# netx90_app register map
File version: 1.0
CPU: CM4 r0p1, little endian, MPU, FPU, 4 interrupt priority bits, 78 interrupts
Registers are 32-bit, read-write, reset 0x0 unless marked. A register's access mark holds for its fields unless they carry their own. Offsets are from the block's base; [hi:lo] are bit positions; {n}, {i} and the like mark numbered series.

## i2c_app
Base 0xFF801080
Same registers: i2c_xpic_app 0xFF900340
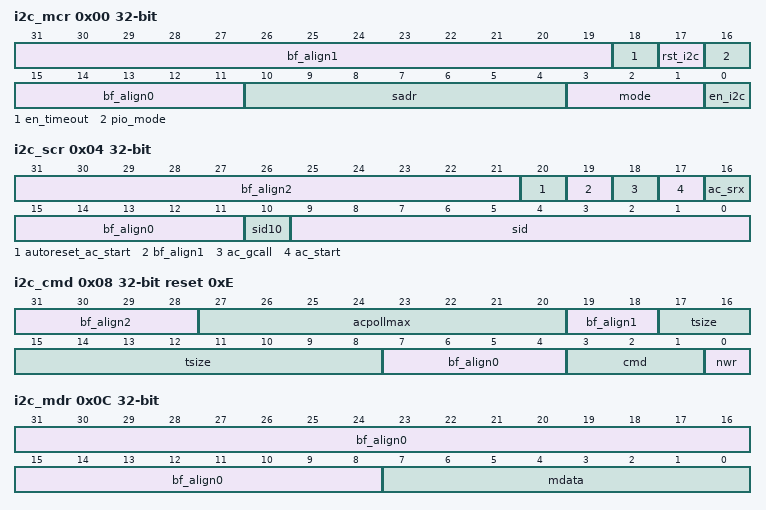
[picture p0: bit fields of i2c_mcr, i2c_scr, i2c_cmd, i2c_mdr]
0x00 i2c_mcr (reset mask 0x707FF) — I2C master control register:
  [31:19] bf_align1 — bitField alignment value for aeabi compatibility
  [18] en_timeout — Enable I2C command timeout detection. Enabling the timeout detection is recommended to prevent the module from stalling if another device holds the I2C signals permanently low. For details, see the description of bit i2s_sr.timeout.
  [17] rst_i2c — Reset the I2C bus-state-detection logic. To avoid conflicts with other masters, some I2C bus states, which are important when there are multiple masters on the I2C bus, are always monitored, even if the I2C module is disabled. For details, see bits i2c_sr.started and i2c.bus_master. However, it may happen that bus states are detected which lock up the I2C module. E.g. hazards during power-up or IO configuration or sequences, which are not I2C compliant, can cause a lock-up. This bit can be used to escape from such a situation. Write a '1' here to reset the I2C bus-state-detection logic of register i2c_sr. Note: This bit is new since netX51/52. It is always '0' when read.
  [16] pio_mode — If this bit is set, SCL and SDA can be controlled directly by register i2c_pio (e.g. to access devices being incompatible with I2C). In PIO mode, the I2C controller state machine is disabled: FIFOs are not used, no IRQs will be set, and no DMA controlling is possible.
  [15:11] bf_align0 — bitField alignment value for aeabi compatibility
  [10:4] sadr — 7-bit slave address sent after (r)START: For 10-bit addressing, the first byte (10-bit start '11110', address bits[9:8] must be programmed here. The second start byte (lower slave address bits) must be on top of the master FIFO (i2c_mdr). This register must be rewritten (even if the value does not change) to address another slave in the 10-bit mode (run 2-byte start sequence). The register must not be rewritten before a repeated START on the same 10-bit addressed slave (run 1-byte start sequence e.g. write to read change).
  [3:1] mode — I2C-speed-mode: If this device is used as a slave only, the mode should be set to the data rate generated by the fastest master on the I2C-bus for appropriate input filtering and spike suppression. The programmed mode defines also the SDA hold time after a falling edge of SCL. { | | Value Mode SDA hold time after SCL low 000 Fast/Standard mode, 50 kbit/s 630ns 001 Fast/Standard mode, 100 kbit/s 630ns 010 Fast/Standard mode, 200 kbit/s 630ns 011 Fast/Standard mode, 400 kbit/s 310ns 100 High-speed mode, 800 kbit/s 150ns 101 High-speed mode, 1.2 Mbit/s 70ns 110 High-speed mode, 1.7 Mbit/s 70ns 111 High-speed mode, 3.4 Mbit/s 30ns}
  [0] en_i2c — Global I2C controller enable 1: Enable I2C controller 0: Disable I2C controller Disabling the I2C module during a transfer will immediately disconnect the I2C module from the bus without generating a STOP. The internal I2C state machine will be set back to initial/idle state. The I2C bus-state-detection for the bits i2c_sr.bus_master and i2c_sr.started are performed even if the module is disabled. For details, see these bits.
0x04 i2c_scr (reset mask 0x1707FF) — I2C slave control register:
  [31:21] bf_align2 — bitField alignment value for aeabi compatibility
  [20] autoreset_ac_start — Auto reset ac_start (ac_start must be set again after any (r)START): 0: ac_start will not be reset automatically (netX 50-compatible, but not recommended) 1: Reset ac_start after this slave acknowledged a start sequence (recommended)
  [19] bf_align1 — bitField alignment value for aeabi compatibility
  [18] ac_gcall — General call acknowledge: 0: Do not generate an acknowledge after a general call 1: Generate an acknowledge after a general call
  [17] ac_start — Enable start sequence acknowledge: If the received address matches the sid-bits, the start-byte (2 bytes if sid10 is set) will be acknowledged. If the master requests a read transfer, a slave FIFO read access will be carried out immediately after the acknowledge, i.e. valid data must be present in the slave FIFO before enabling the acknowledge. If autoreset_ac_start is enabled, the controller will automatically reset this bit. If it is not enabled, the software should reset this bit after the start sequence has been acknowledged to avoid acknowledge and FIFO errors after the next (r)START. 0: Do not generate an acknowledge after the start sequence 1: Generate an acknowledge after the start sequence This bit is writable, but can also be changed by hardware.
  [16] ac_srx — Enable slave-receive-data acknowledge: 0: Do not acknowledge receive bytes 1: Acknowledge receive bytes If the slave FIFO is full, receive data will not be acknowledged.
  [15:11] bf_align0 — bitField alignment value for aeabi compatibility
  [10] sid10 — 10-bit slave device ID/address: 0: Wait for 7-bit slave address after (r)START 1: Wait for 10-bit slave address after (r)START
  [9:0] sid — Slave device ID/address: External masters can address this device (this I2C module in slave mode) by the ID/address programmed here. If sid10 is not set, bits 9 to 7 will be ignored.
0x08 i2c_cmd reset 0xE (reset mask 0xFF3FF0F) — I2C master command register:
  [31:28] bf_align2 — bitField alignment value for aeabi compatibility
  [27:20] acpollmax — Number of tries (acpollmax+1, i.e. 1 to 256) for start sequence acknowledge polling: For 7-bit addressing, acknowledge polling START and the first byte containing the slave address (i2c_mcr.sadr) will be repeated up to acpollmax+1 times until a slave generates an acknowledge. If no acknowledge is received within acpollmax+1 tries, IRQ cmd_err will be generated. For 10-bit-addressing, the 2-byte start sequence is performed. The second address byte (lower address bits) must be on top of the master FIFO (i2c_mdr). For subsequent transfers, the value programmed in tsize has to ignore this byte. The programmed value of acpollmax will count down during acknowledge polling after each start sequence. This bit is writable, but can also be changed by hardware.
  [19:18] bf_align1 — bitField alignment value for aeabi compatibility
  [17:8] tsize — Transfer tsize+1 bytes (1...1024): If no acknowledge is generated by the slave (receiver), write transfers will be terminated and IRQ cmd_err will be generated. For 10-bit-addressing, the second start-byte (lower address bits) must be on top of the master FIFO. For subsequent transfers, the value programmed here has to ignore this byte. This value will count down during transfers after each byte. This bit is writable, but can also be changed by hardware.
  [7:4] bf_align0 — bitField alignment value for aeabi compatibility
  [3:1] cmd — I2C sequence command: All commands will generate IRQ cmd_ok or IRQ cmd_err. A successful command termination will always generate IRQ cmd_ok. In case of an unsuccessful command termination, IRQ cmd_err will be set. { | | 000 START Generate (r)START-condition 001 S_AC Acknowledge-polling: generate up to acpollmax+1 START-sequences (until acknowledged by slave) 010 S_AC_T Run S_AC, then transfer tsize+1 bytes from/to master FIFO. Not to be continued 011 S_AC_TC Run S_AC, then transfer tsize+1 bytes from/to master FIFO. To be continued 100 CT Continued transfer not to be continued 101 CTC Continued transfer to be continued 110 STOP Generate STOP-condition 111 IDLE Nothing to do, last command finished, break current command } Sequences including read transfers that are not to be continued (S_AC_T, CT with 'nwr' bit set) will not generate an acknowledge after the last received byte (read transfer ends). Read transfers that are to be continued (S_AC_TC, CTC) will generate an acknowledge after the last received byte and must be followed by CT or CTC. Before continued transfers (CT, CTC), a command including START (START, S_AC, S_AC_T, S_AC_TC) must be executed to generate a valid I2C sequence. STOP must always be executed by software to free the bus after transfer end. STOP is not included in any command sequence and never executed automatically by this module. Some commands are handled as sequences (i.e. after setting S_AC_T, first S_AC then CT will be seen when read). You need not poll for IDLE here before setting up a new command, but you have to wait for cmd_ok or cmd_err status flags of register i2c_irqsr to be set. This bit is writable, but can also be changed by hardware.
  [0] nwr — Transfer direction (not-write/read): 0: cmd will be executed as write 1: cmd will be executed as read Master FIFO-requests (IRQ and DMA) are generated depending on this direction flag.
0x0C i2c_mdr (reset mask 0xFF) — I2C master data register (master FIFO): There is only one FIFO for both receive and transmit master data with a depth of 16 bytes. For a master write access, data read from the FIFO is is sent via I2C. For a master read access, data received from I2C is written into the FIFO. In case of imminent data transfer failure (read transfer and FIFO is full or write transfer and FIFO is empty), the transfer will be paused. To continue the transfer, the FIFO must be handled first (filled for transmit, read out for receive). Note: The FIFO behavior has been changed: For netX 51/52/56 and older versions, the current command was aborted and the cmd_err was raised.
  [31:8] bf_align0 — bitField alignment value for aeabi compatibility
  [7:0] mdata — I2C master transmit or receive data: Transmit data will be removed from the FIFO after the receiving slave has generated the corresponding acknowledge. Transmit data that has not been acknowledged will not be removed from the FIFO.
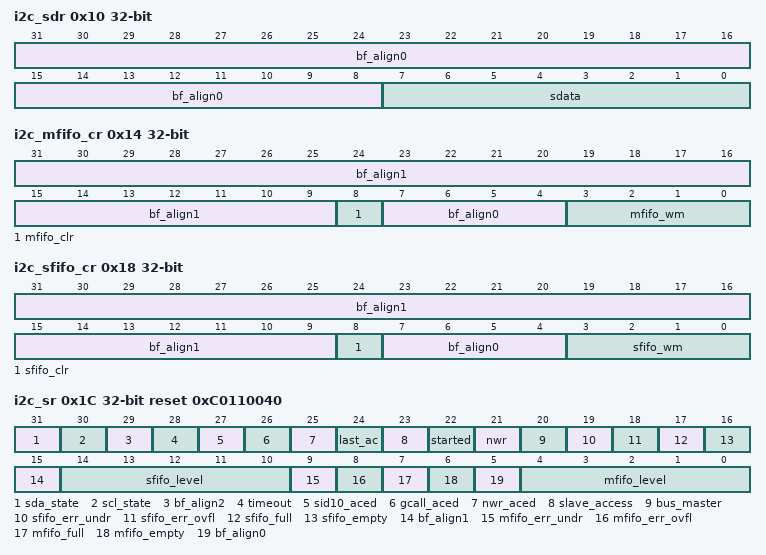
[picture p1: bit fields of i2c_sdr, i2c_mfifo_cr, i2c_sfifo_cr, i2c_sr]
0x10 i2c_sdr (reset mask 0xFF) — I2C slave data register (slave FIFO): There is only one FIFO for both receive and transmit slave data with a depth of 16 bytes. For a read access of an external master, data sent by this slave is read from the FIFO. For a write access of an external master, data received by this slave is written into the FIFO. A transfer is initiated after the detection of I2C-start-sequence to the device address (i2c_scr.sid, sreq IRQ) which is acknowledged by this device (i2c_scr.ac_start). For read transfers, sent data is read from the FIFO immediately after the detection of the acknowledge on the I2C-bus. SDA will be driven with the next data MSB immediately after the acknowledge SCL high phase. In case of a master read transfer and slave FIFO underrun, corrupted data will be sent to the master and the IRQ fifo_err will be set. In case of a master write transfer and slave FIFO is full, no acknowledge will be generated for the last received byte. No FIFO overflow will occur, but the last transferred byte (not acknowledged) will be lost and has to be sent again by the master.
  [31:8] bf_align0 — bitField alignment value for aeabi compatibility
  [7:0] sdata — I2C slave transmit or receive data: The software must handle i2c_scr.ac_start correctly to avoid FIFO errors after (r)START.
0x14 i2c_mfifo_cr (reset mask 0x10F) — I2C master FIFO control register:
  [31:9] bf_align1 — bitField alignment value for aeabi compatibility
  [8] mfifo_clr — Clear master data FIFO, write only bit. This bit is writable, but can also be changed by hardware.
  [7:4] bf_align0 — bitField alignment value for aeabi compatibility
  [3:0] mfifo_wm — Master FIFO watermark for the generation of IRQ mfifo_req: If the master is the transmitter (enabled and i2c_cmd.nwr is 0), IRQ mfifo_req is generated if mfifo_level<mfifo_wm. If the master is the receiver (enabled and i2c_cmd.nwr is 1), IRQ mfifo_req is generated if mfifo_level>mfifo_wm. Note: Set the watermark to 0 at transfer end to avoid further IRQ generation.
0x18 i2c_sfifo_cr (reset mask 0x10F) — I2C slave FIFO control register:
  [31:9] bf_align1 — bitField alignment value for aeabi compatibility
  [8] sfifo_clr — Clear slave data FIFO, write only bit. This bit is writable, but can also be changed by hardware.
  [7:4] bf_align0 — bitField alignment value for aeabi compatibility
  [3:0] sfifo_wm — Slave FIFO watermark for the generation of IRQ sfifo_req: If the slave is the transmitter (start sequence with set read bit was acknowledged by this slave), IRQ sfifo_req is generated if sfifo_level<sfifo_wm. If the slave is not the transmitter (is receiver or not selected), IRQ sfifo_req is generated if sfifo_level>sfifo_wm.
0x1C i2c_sr reset 0xC0110040 (reset mask 0xDFFF7FDF) — I2C status register:
  [31] sda_state — SDA signal state sampled and filtered from bus (e.g. to detect bus blockings) This is a read-only status bit.
  [30] scl_state — SCL signal state sampled and filtered from bus (e.g. to detect bus blockings) This is a read-only status bit.
  [29] bf_align2 — bitField alignment value for aeabi compatibility
  [28] timeout — I2C command timeout detection (for I2C master). I2C slaves can stretch low SCL phases by holding the SCL line low. The master must detect this and wait until the SCL line is released before the current transfer can continue. In error cases, the I2C bus can be blocked permanently by a low signal state of SCL. The reason for the blocking can be e.g. a crashed I2C slave or a false I/O configuration. To escape from such a situation, a timeout watchdog is implemented: A timeout will be detected if the SCL line is held low for more than 256 SCL periods. In this case, the recent command will be terminated and IRQ cmd_err will be set. The timeout detection must be enabled by bit i2c_mcr.en_timeout. It is disabled by default for backward compatibility. However, enabling is strongly recommended. If timeout is detected, the status bit must be cleared before a new command can be applied. This status bit can be cleared by writing a '1' to it or when bit i2c_mcr.rst_i2c performs a reset of the bus-state-detection logic.
  [27] sid10_aced — 10-bit slave address acknowledge state. { | 0: There was no 10-bit slave address or it was not acknowledged. 1: A 10-bit slave address was broadcasted and a slave acknowledged this broadcast. I.e. for the master side: A 10-bit slave was addressed and the slave acknowledged. I.e. for the slave side: A master broadcasted a start with the address programmed in register i2c_scr.sid and the i2c module acknowledged this broadcast as bit i2c_scr.ac_start is set.} This read-only status bit is cleared automatically when the module detects a STOP or when register i2c_mcr is written (e.g. to perform a module reset by bit i2c_mcr.rst_i2c or to address another slave by changing the bits i2c_mcr.sadr). Remember that during rSTART, the master will generate only the first START-byte.
  [26] gcall_aced — General call acknowledge state. 0: No general call start-byte, or general call start-byte was not acknowledged. 1: The slave side of the i2c module received and acknowledged a general call. Bit i2c_scr.ac_gcall controls the acknowledging of a general call. This read-only status bit will be cleared automatically if the last start-byte is not a general call or if it is a general call but bit i2c_scr.ac_gcall is not set. This bit is forced to '0' when the bit i2c_mcr.rst_i2c performs a reset of the bus-state-detection logic. Note: The bit has no function for the master side of the i2c module
  [25] nwr_aced — Transfer direction (nwr-bit) of the last acknowledged start-byte (or 2-byte start sequence for 10-bit addressing). 0: The last acknowledged start-byte defined a write transfer. 1: The last acknowledged start-byte defined a read transfer. Slave FIFO requests generating IRQ and DMA requests depend on this direction flag. This read-only status bit is forced to '0' when bit i2c_mcr.rst_i2c performs a reset of the bus-state-detection logic.
  [24] last_ac — Last acknowledge detected on bus. 0: SDA was high at the last acknowledge, i.e. no acknowledge. 1: SDA was low at the last acknowledge, i.e. acknowledge. This read-only status bit is forced to '0' when bit i2c_mcr.rst_i2c performs a reset of the bus-state-detection logic.
  [23] slave_access — Slave access state. 0: No slave access to this device. 1: A master addressed this slave device. This read-only status bit is set if a start-byte (2 bytes for 10-bit address) containing the address programmed in register i2c_scr.sid has been received. This bit is always reset to 0 during START or STOP. This bit is forced to '0' when bit i2c_mcr.rst_i2c performs a reset of the bus-state-detection logic. Note: This bit does not depend on whether the start-byte has been acknowledged or not.
  [22] started — START condition detection: 0: The bus is idle (STOP was detected, not started). 1: (r)START was detected on the bus. The bus is occupied. This detection will also take place while the module is disabled. This is important if there are multiple I2C masters on the bus: If another master occupies the bus while the I2C module is disabled, the I2C module must not start a transfer, before the other master has released the bus. Use bit i2c_mcr.rst_i2c to force this read-only status bit to '0', e.g. in order to escape from an accidentally detected START or a START that is not followed by a STOP.
  [21] nwr — Transfer direction detected after last (r)START. 0: The last start-byte defined a write transfer. 1: The last start-byte defined a read transfer. This read-only status bit is always reset to 0 during (r)START. This bit is forced to '0' when bit i2c_mcr.rst_i2c performs a reset of the bus-state-detection logic. Note: This bit does not depend on whether the start-byte has been acknowledged or not.
  [20] bus_master — Bus arbitration state. 0: Master lost I2C bus arbitration, bus is busy by another master. 1: Master gains I2C bus arbitration or bus is idle. This read-only status bit is set when the monitored bus state does not match the bus state expected by the I2C module. The bit is reset, when a STOP is detected. This detection will also take place while the module is disabled. This is important if there are multiple I2C masters on the bus: If another master occupies the bus while the I2C module is disabled, the I2C module must not start a transfer, before the other master has released the bus. Use bit i2c_mcr.rst_i2c to force this bit to '0', e.g. in order to escape from an arbitration loss not followed by a STOP.
  [19] sfifo_err_undr — Slave FIFO underrun error occurred. Data is lost and the slave FIFO must be cleared by bit i2c_sfifo_cr.sfifo_clr. Clearing the slave FIFO will also clear this read-only status bit.
  [18] sfifo_err_ovfl — Slave FIFO overflow error occurred. Data is lost and the slave FIFO must be cleared by bit i2c_sfifo_cr.sfifo_clr. Clearing the slave FIFO will also clear this read-only status bit.
  [17] sfifo_full — Slave FIFO is full (1 if full) This is a read-only status bit.
  [16] sfifo_empty — Slave FIFO is empty (1 if empty) This is a read-only status bit.
  [15] bf_align1 — bitField alignment value for aeabi compatibility
  [14:10] sfifo_level — Slave FIFO level (0..16) This is a read-only status bit field.
  [9] mfifo_err_undr — Master FIFO underrun error occurred. Data is lost and the master FIFO must be cleared by bit i2c_mfifo_cr.mfifo_clr. Clearing the master FIFO will also clear this read-only status bit. Note: This can only happen in case of a CPU read accesses to an empty FIFO. The I2C statemachine will pause external transfers before FIFO underrun occurs.
  [8] mfifo_err_ovfl — Master FIFO overflow error occurred. Data is lost and the master FIFO must be cleared by bit i2c_mfifo_cr.mfifo_clr. Clearing the master FIFO will also clear this read-only status bit. Note: This can only happen in case of a CPU write accesses to a full FIFO. The I2C statemachine will pause external transfers before FIFO overflow occurs.
  [7] mfifo_full — Master FIFO is full (1 if full) This is a read-only status bit.
  [6] mfifo_empty — Master FIFO is empty (1 if empty) This is a read-only status bit.
  [5] bf_align0 — bitField alignment value for aeabi compatibility
  [4:0] mfifo_level — Master FIFO level (0..16) This is a read-only status bit field.
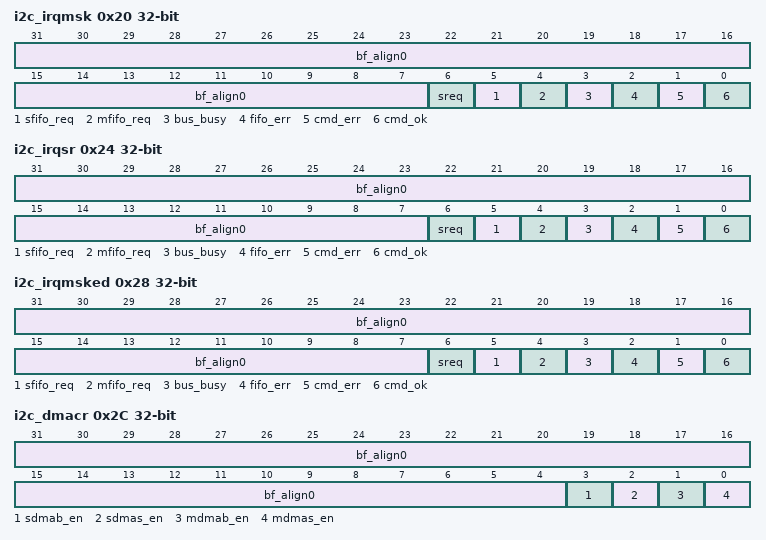
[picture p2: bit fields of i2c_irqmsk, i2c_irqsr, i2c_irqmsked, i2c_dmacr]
0x20 i2c_irqmsk (reset mask 0x7F) — I2C interrupt mask set or clear register: These bits have AND-mask character. The corresponding IRQ will generate the module IRQ only if the mask bit is set. Changing a mask bit from '0' to '1' will clear the corresponding raw IRQ state. For a detailed IRQ description, see i2c_irqraw.
  [31:7] bf_align0 — bitField alignment value for aeabi compatibility
  [6] sreq — Slave request interrupt mask
  [5] sfifo_req — Slave FIFO action request interrupt mask
  [4] mfifo_req — Master FIFO action request interrupt mask
  [3] bus_busy — External I2C-bus is busy interrupt mask
  [2] fifo_err — FIFO error interrupt mask
  [1] cmd_err — Command error interrupt mask
  [0] cmd_ok — Command OK interrupt mask
0x24 i2c_irqsr (reset mask 0x7F) — I2C interrupt state register (raw interrupt before masking): Writing '1' will clear the corresponding IRQ.
  [31:7] bf_align0 — bitField alignment value for aeabi compatibility
  [6] sreq — Unmasked slave request interrupt state: Purpose: Set up slave FIFO 1: External master was running START-sequence and requested this slave 0: Slave is not requested
  [5] sfifo_req — Unmasked slave FIFO action request interrupt state: Purpose: Slave FIFO should be updated 1: Slave FIFO request: i2c_sr.sfifo_level is above or below i2c_sfifo_cr.sfifo_wm (see description i2c_sfifo_cr) 0: Slave FIFO state not critical
  [4] mfifo_req — Unmasked master FIFO action request interrupt state: Purpose: Master FIFO should be updated 1: Master FIFO request: i2c_sr.mfifo_level is above or below i2c_mfifo_cr.mfifo_wm (see description i2c_mfifo_cr) 0: Master FIFO state not critical
  [3] bus_busy — Unmasked external I2C-bus is busy interrupt state: Purpose: Detect I2C-bus arbitration loss 1: Master did not gain the requested bus access because another master accessed the bus 0: Bus is idle or no transfer is requested by this master
  [2] fifo_err — Unmasked FIFO error interrupt state: Purpose: Detect FIFO errors/transfer failures 1: FIFO error occurred, check register i2c_sr 0: FIFOs ok
  [1] cmd_err — Unmasked command error interrupt state: Purpose: Check last command termination 1: Last command finished erroneously 0: Command not finished, no command or command finished successfully
  [0] cmd_ok — Unmasked command OK interrupt state: Purpose: Check last command termination 1: Last command finished successfully 0: Command not finished, no command or command finished erroneously
0x28 i2c_irqmsked ro (reset mask 0x7F) — I2C masked interrupt state register: If one of these bits is set, the I2C IRQ will be set to the interrupt controller. For a detailed IRQ description, see i2c_irqraw.
  [31:7] bf_align0 — bitField alignment value for aeabi compatibility
  [6] sreq — Masked slave request interrupt state
  [5] sfifo_req — Masked slave FIFO action request interrupt state
  [4] mfifo_req — Masked master FIFO action request interrupt state
  [3] bus_busy — Masked external I2C-bus is busy interrupt state
  [2] fifo_err — Masked FIFO error interrupt state
  [1] cmd_err — Masked command error interrupt state
  [0] cmd_ok — Masked command OK interrupt state
0x2C i2c_dmacr (reset mask 0xF) — I2C DMA control register: Required settings for the DMA controller: - DMA transfer size to/from I2C module: Byte - DMA burst length to/from I2C module: 4 DMA burst requests will be generated if the corresponding FIFO contains more than 4 bytes (receive case) or if more than 4 bytes are writable to the corresponding FIFO (transmit case). DMA single transfer requests will be generated if the corresponding FIFO contains more than 1 byte (receive case) or if more than 1 byte is writable to the corresponding FIFO (transmit case). No further DMA requests will be generated if all transmit data is written to the master FIFO and the i2c module is the DMA flow controller (for master data only). Once all data is written to the master FIFO, the last burst/single request will be generated for the DMA controller. If the DMA controller sets DMACTC (terminal count) to indicate the end of transfer, the corresponding bit will be cleared. If one of the bits of this register is set to 0 by software and a DMA transfer has been requested before, the DMA controller will perform one last transfer to reset DMA request signals.
  [31:4] bf_align0 — bitField alignment value for aeabi compatibility
  [3] sdmab_en — Enable DMA burst requests for I2C slave data. The DMA controller must be the flow controller. This bit is writable, but can also be changed by hardware.
  [2] sdmas_en — Enable DMA single requests for I2C slave data. The DMA controller must be the flow controller. This bit is writable, but can also be changed by hardware.
  [1] mdmab_en — Enable DMA burst requests for I2C master data. The I2C module is the flow controller (i.e. peripheral-controlled flow control). Both, single and burst requests must be enabled. This bit is writable, but can also be changed by hardware.
  [0] mdmas_en — Enable DMA single requests for I2C master data. The I2C module is the flow controller (i.e. peripheral-controlled flow control). Both, single and burst requests must be enabled. This bit is writable, but can also be changed by hardware.
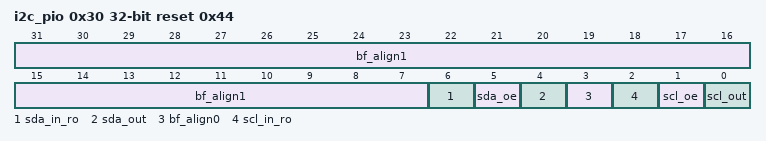
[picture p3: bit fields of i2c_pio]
0x30 i2c_pio reset 0x44 (reset mask 0x77) — PIO mode register: This register can directly control the I2C signals SCL and SDA if pio_mode is enabled in register i2c_mcr. In PIO mode, the I2C controller state machine is disabled, thus, no FIFO action takes place, no IRQs will be set, and no DMA-controlling is possible. Note: To avoid external driving conflicts, the I2C signals SCL and SDA are never driven active-high according to the I2C bus specification. The high level of these signals is realized by a pull-up (of the pad or externally) and by setting the appropriate output enable to 0 (scl_oe, sda_oe) instead of driving the level active-high. Driving the signals directly by enabling the outputs (programming the bits sda_oe or scl_oe to '1') can lead to driving conflicts and could cause damage.
  [31:7] bf_align1 — bitField alignment value for aeabi compatibility
  [6] sda_in_ro — SDA input state (read-only)
  [5] sda_oe — SDA output enable 0: Do not drive SDA, switch pad to high-z. 1: Drive SDA, switch pad to programmed sda_out-state
  [4] sda_out — Driving level of SDA (1: high, 0: low) if output is enabled (sda_oe is set)
  [3] bf_align0 — bitField alignment value for aeabi compatibility
  [2] scl_in_ro — SCL input state (read-only)
  [1] scl_oe — SCL output enable 0: Do not drive SCL, switch pad to high-z. 1: Drive SCL, switch pad to programmed scl_out-state
  [0] scl_out — Driving level of SCL (1: high, 0: low) if output is enabled (scl_oe is set)
